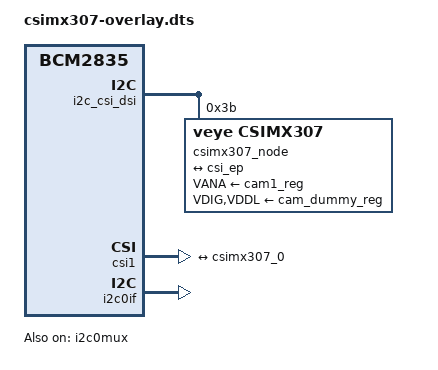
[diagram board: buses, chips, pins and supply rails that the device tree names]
// SPDX-License-Identifier: GPL-2.0-only
// Definitions for CS-MIPI-IMX307 camera module on VC I2C bus
/dts-v1/;
/plugin/;

//#include <dt-bindings/gpio/gpio.h>

/{
	compatible = "brcm,bcm2835";

	i2c_frag: fragment@0 {
		target = <&i2c_csi_dsi>;
		__overlay__ {
			#address-cells = <1>;
			#size-cells = <0>;
			status = "okay";

			csimx307_node: csimx307@3b {
				compatible = "veye,csimx307";
				reg = <0x3b>;
				status = "okay";

				clocks = <&cam1_clk>;
				clock-names = "xclk";

				VANA-supply = <&cam1_reg>;	/* 2.8v */
				VDIG-supply = <&cam_dummy_reg>;	/* 1.8v */
				VDDL-supply = <&cam_dummy_reg>;	/* 1.2v */
		            rotation = <0>;
		            orientation = <2>;

				port {
					csimx307_0: endpoint {
						remote-endpoint = <&csi_ep>;
						clock-lanes = <0>;
						data-lanes = <1 2>;
						clock-noncontinuous;
						link-frequencies =
							/bits/ 64 <297000000>;
					};
				};
			};
		};
	};

	csi_frag: fragment@1 {
		target = <&csi1>;
		csi: __overlay__ {
			status = "okay";

			port {
				csi_ep: endpoint {
					remote-endpoint = <&csimx307_0>;
					clock-lanes = <0>;
					data-lanes = <1 2>;
					clock-noncontinuous;
				};
			};
		};
	};
	
	fragment@2 {
		target = <&i2c0if>;
		__overlay__ {
			status = "okay";
		};
	};

	clk_frag: fragment@3 {
		target = <&cam1_clk>;
		__overlay__ {
			clock-frequency = <24000000>;
			status = "okay";
		};
	};

	fragment@4 {
		target = <&i2c0mux>;
		__overlay__ {
			status = "okay";
		};
	};
	fragment@5 {
		target = <&csi1>;
		__dormant__ {
			compatible = "brcm,bcm2835-unicam-legacy";
		};
	};

	__overrides__ {
		media-controller = <0>,"!5";
		rotation = <&csimx307_node>,"rotation:0";
		orientation = <&csimx307_node>,"orientation:0";
		cam0 = <&i2c_frag>, "target:0=",<&i2c_csi_dsi0>,
		       <&csi_frag>, "target:0=",<&csi0>,
		       <&clk_frag>, "target:0=",<&cam0_clk>,
		       <&csimx307_node>, "clocks:0=",<&cam0_clk>,
		       <&csimx307_node>, "VANA-supply:0=",<&cam0_reg>;
	};
};

